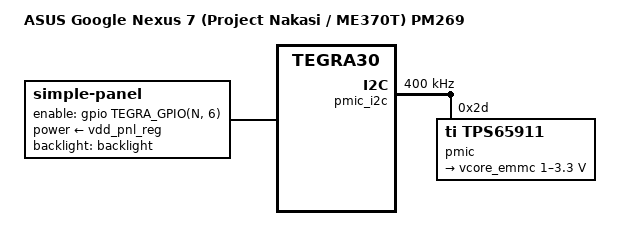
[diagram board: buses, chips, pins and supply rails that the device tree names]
// SPDX-License-Identifier: GPL-2.0-or-later
/dts-v1/;

#include <dt-bindings/input/gpio-keys.h>
#include <dt-bindings/input/linux-event-codes.h>

#include "tegra30-asus-grouper-common.dtsi"

/ {
	model = "ASUS Google Nexus 7 (Project Nakasi / ME370T) PM269";
	compatible = "asus,grouper", "nvidia,tegra30";

	pmic_i2c: i2c@7000d000 {
		status = "okay";
		clock-frequency = <400000>;

		/* Texas Instruments TPS659110 PMIC */
		pmic: tps65911@2d {
			compatible = "ti,tps65911";
			reg = <0x2d>;

			interrupts = <GIC_SPI 86 IRQ_TYPE_LEVEL_HIGH>;
			#interrupt-cells = <2>;
			interrupt-controller;

			ti,system-power-controller;

			#gpio-cells = <2>;
			gpio-controller;

			regulators {
				/* eMMC VDD */
				vcore_emmc: ldo1 {
					regulator-name = "vdd_emmc_core";
					regulator-min-microvolt = <1000000>;
					regulator-max-microvolt = <3300000>;
					regulator-always-on;
				};
			};
		};
	};

	panel: panel {
		compatible = "simple-panel";

		power-supply = <&vdd_pnl_reg>;
		enable-gpios = <&gpio TEGRA_GPIO(N, 6) GPIO_ACTIVE_HIGH>;

		backlight = <&backlight>;

		display-timings {
			timing@0 {
				/* 1280x800@60Hz */
				clock-frequency = <68000000>;

				hactive = <800>;
				hfront-porch = <24>;
				hback-porch = <32>;
				hsync-len = <24>;

				vactive = <1280>;
				vfront-porch = <5>;
				vback-porch = <32>;
				vsync-len = <1>;
			};
		};
	};
};
